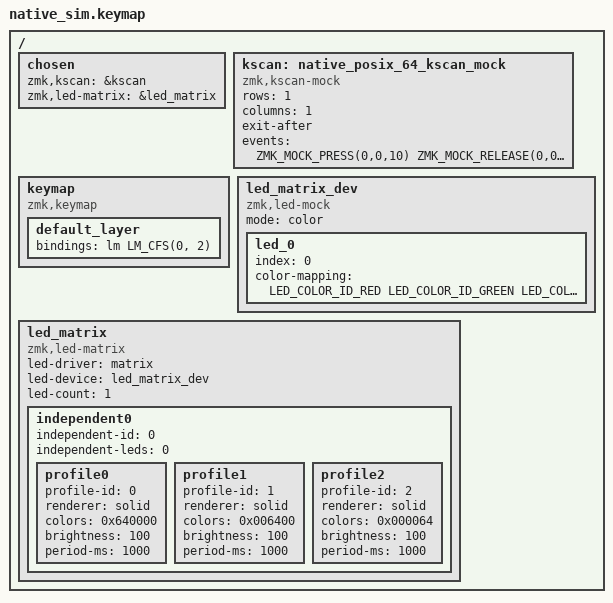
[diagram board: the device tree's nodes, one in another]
#include <dt-bindings/zmk/keys.h>
#include <dt-bindings/zmk/kscan_mock.h>
#include <dt-bindings/zmk/led_matrix.h>
#include <dt-bindings/led/led.h>
#include <behaviors.dtsi>

/ {
    chosen {
        zmk,kscan = &kscan;
        zmk,led-matrix = &led_matrix;
    };

    kscan: native_posix_64_kscan_mock {
        compatible = "zmk,kscan-mock";
        rows = <1>;
        columns = <1>;
        exit-after;
        events = <
            ZMK_MOCK_PRESS(0,0,10)
            ZMK_MOCK_RELEASE(0,0,10)
        >;
    };

    keymap {
        compatible = "zmk,keymap";

        default_layer {
            bindings = <&lm LM_CFS(0, 2)>;
        };
    };

    led_matrix_dev: led_matrix_dev {
        compatible = "zmk,led-mock";
        mode = "color";

        led_0 { index = <0>; color-mapping = <LED_COLOR_ID_RED LED_COLOR_ID_GREEN LED_COLOR_ID_BLUE>; };
    };

    led_matrix: led_matrix {
        compatible = "zmk,led-matrix";
        led-driver = "matrix";
        led-device = <&led_matrix_dev>;
        led-count = <1>;

        independent0 {
            independent-id = <0>;
            independent-leds = <0>;

            profile0 {
                profile-id = <0>;
                renderer = "solid";
                colors = <0x640000>;
                brightness = <100>;
                period-ms = <1000>;
            };

            profile1 {
                profile-id = <1>;
                renderer = "solid";
                colors = <0x006400>;
                brightness = <100>;
                period-ms = <1000>;
            };

            profile2 {
                profile-id = <2>;
                renderer = "solid";
                colors = <0x000064>;
                brightness = <100>;
                period-ms = <1000>;
            };
        };
    };
};
